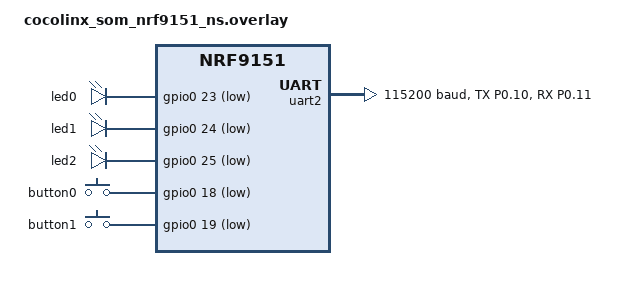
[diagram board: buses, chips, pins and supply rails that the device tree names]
/*
 * Copyright (c) 2024 Nordic Semiconductor ASA
 *
 * SPDX-License-Identifier: LicenseRef-Nordic-5-Clause
 *
 * CocoLinx nRF9151-SOM Devicetree Overlay Example
 *
 * This file is provided as a reference only.
 * Copy the required configurations into each example's
 * board overlay file.
 */



#include <samples/cellular/nrf91_no_bootloader_partitions.dtsi>
#include <samples/cellular/nrf91_sram_partitions.dtsi>
#include <zephyr/dt-bindings/input/input-event-codes.h>

/ {
    leds {
        compatible = "gpio-leds";

        led0: led_0 {
            gpios = <&gpio0 23 GPIO_ACTIVE_LOW>;
            label = "led0";
        };

        led1: led_1 {
            gpios = <&gpio0 24 GPIO_ACTIVE_LOW>;
            label = "led1";
        };

        led2: led_2 {
            gpios = <&gpio0 25 GPIO_ACTIVE_LOW>;
            label = "led2";
        };
    };

    buttons {
        compatible = "gpio-keys";

        button0: button_0 {
            gpios = <&gpio0 18 (GPIO_PULL_UP | GPIO_ACTIVE_LOW)>;
            label = "button0";
            zephyr,code = <INPUT_KEY_0>;
        };

        button1: button_1 {
            gpios = <&gpio0 19 (GPIO_PULL_UP | GPIO_ACTIVE_LOW)>;
            label = "button1";
            zephyr,code = <INPUT_KEY_1>;
        };
    };

    aliases {
        led0 = &led0;
        led1 = &led1;
        led2 = &led2;
        button0 = &button0;
        button1 = &button1;
    };
};

&pinctrl {
	uart2_default: uart2_default {
		group1 {
			psels = <NRF_PSEL(UART_TX, 0, 10)>;
		};
		group2 {
			psels = <NRF_PSEL(UART_RX, 0, 11)>;
			bias-pull-up;
		};
	};
	uart2_sleep: uart2_sleep {
		group1 {
			psels = <NRF_PSEL(UART_TX, 0, 10)>,
				<NRF_PSEL(UART_RX, 0, 11)>;
			low-power-enable;
		};
	};

	// spi3_default: spi3_default {
	// 	group1 {
	// 		psels = <NRF_PSEL(SPIM_SCK, 0, 29)>,
	// 			<NRF_PSEL(SPIM_MOSI, 0, 31)>,
	// 			<NRF_PSEL(SPIM_MISO, 0, 13)>;
	// 	};
	// };

	// spi3_sleep: spi3_sleep {
	// 	group1 {
	// 		psels = <NRF_PSEL(SPIM_SCK, 0, 29)>,
	// 			<NRF_PSEL(SPIM_MOSI, 0, 31)>,
	// 			<NRF_PSEL(SPIM_MISO, 0, 13)>;
	// 		low-power-enable;
	// 	};
	// };

	// i2c1_default: i2c1_default {
	// 	group1 {
	// 		psels = <NRF_PSEL(TWIM_SDA, 0, 8)>,
	// 			<NRF_PSEL(TWIM_SCL, 0, 9)>;
	// 	};
	// };

	// i2c1_sleep: i2c1_sleep {
	// 	group1 {
	// 		psels = <NRF_PSEL(TWIM_SDA, 0, 8)>,
	// 			<NRF_PSEL(TWIM_SCL, 0, 9)>;
	// 		low-power-enable;
	// 	};
	// };
};

&uart2 {
	status = "okay";
	current-speed = <115200>;
	pinctrl-0 = <&uart2_default>;
	pinctrl-1 = <&uart2_sleep>;
	pinctrl-names = "default", "sleep";
};

// &spi3 {
// 	compatible = "nordic,nrf-spim";
// 	status = "okay";
// 	pinctrl-0 = <&spi3_default>;
// 	pinctrl-1 = <&spi3_sleep>;
// 	pinctrl-names = "default", "sleep";
// 	cs-gpios = <&gpio0 30 GPIO_ACTIVE_LOW>;
// };

// &i2c1 {
// 	compatible = "nordic,nrf-twim";
// 	status = "okay";
// 	pinctrl-0 = <&i2c1_default>;
// 	pinctrl-1 = <&i2c1_sleep>;
// 	pinctrl-names = "default", "sleep";
// 	clock-frequency = <I2C_BITRATE_FAST>;
// };

// &pwm0 {
// 	status = "okay";
// 	pinctrl-0 = <&pwm0_default>;
// 	pinctrl-1 = <&pwm0_sleep>;
// 	pinctrl-names = "default", "sleep";
// };
